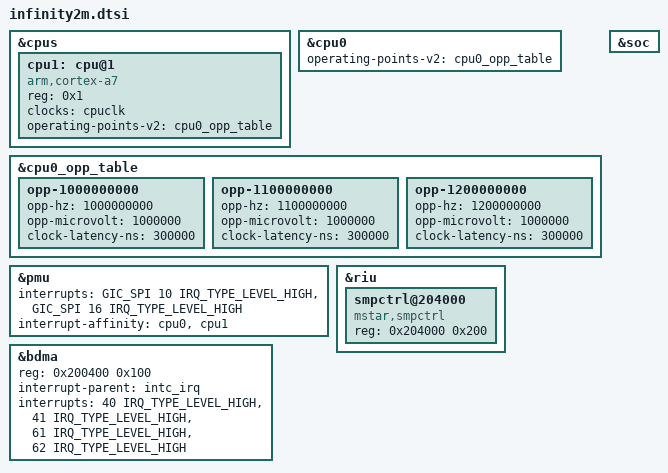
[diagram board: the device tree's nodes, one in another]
// SPDX-License-Identifier: GPL-2.0
/*
 * Copyright (c) 2020 thingy.jp.
 * Author: Daniel Palmer <daniel@thingy.jp>
 */

#include "infinity.dtsi"

/ {
};

&cpus {
	cpu1: cpu@1 {
		device_type = "cpu";
		compatible = "arm,cortex-a7";
		reg = <0x1>;
		clocks = <&cpuclk>;
		clock-names = "cpuclk";
		operating-points-v2 = <&cpu0_opp_table>;
	};
};

&cpu0 {
	operating-points-v2 = <&cpu0_opp_table>;
};

&cpu0_opp_table {
	opp-1000000000 {
		opp-hz = /bits/ 64 <1000000000>;
		opp-microvolt = <1000000>;
		clock-latency-ns = <300000>;
	};

	opp-1100000000 {
		opp-hz = /bits/ 64 <1100000000>;
		opp-microvolt = <1000000>;
		clock-latency-ns = <300000>;
	};

	opp-1200000000 {
		opp-hz = /bits/ 64 <1200000000>;
		opp-microvolt = <1000000>;
		clock-latency-ns = <300000>;
	};
};

&pmu {
		interrupts = <GIC_SPI 10 IRQ_TYPE_LEVEL_HIGH>,
			     <GIC_SPI 16 IRQ_TYPE_LEVEL_HIGH>;
		interrupt-affinity = <&cpu0>, <&cpu1>;
};

&soc {
	//start address for second cpu
	//0x1F20404C
	//0x1F204050
	//0x1F204058 -- unlock
};

&riu {
	smpctrl@204000 {
		compatible = "mstar,smpctrl";
		reg = <0x204000 0x200>;
		status = "okay";
	};
};

&bdma {
	reg = <0x200400 0x100>;
	interrupt-parent = <&intc_irq>;
	interrupts = <40 IRQ_TYPE_LEVEL_HIGH>,
		     <41 IRQ_TYPE_LEVEL_HIGH>,
		     <61 IRQ_TYPE_LEVEL_HIGH>,
		     <62 IRQ_TYPE_LEVEL_HIGH>;
};
